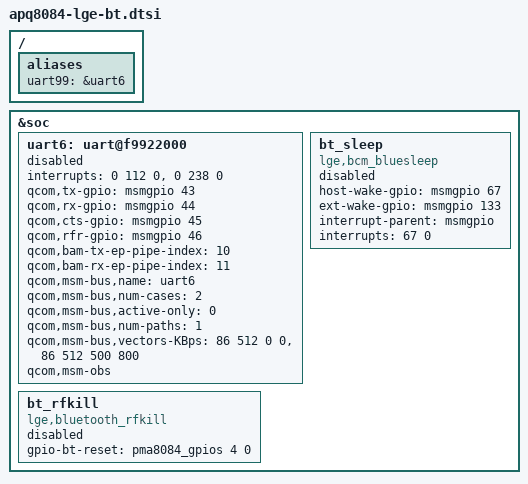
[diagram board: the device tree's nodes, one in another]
/* Copyright (c) 2012, Code Aurora Forum. All rights reserved.
 *
 * This program is free software; you can redistribute it and/or modify
 * it under the terms of the GNU General Public License version 2 and
 * only version 2 as published by the Free Software Foundation.
 *
 * This program is distributed in the hope that it will be useful,
 * but WITHOUT ANY WARRANTY; without even the implied warranty of
 * MERCHANTABILITY or FITNESS FOR A PARTICULAR PURPOSE.  See the
 * GNU General Public License for more details.
 */

/ {
	aliases {
		uart99 = &uart6;
	};
};

&soc {
	uart6: uart@f9922000 { //BLSP6
		status = "disable";
		interrupts = <0 112 0>, <0 238 0>;
		interrupt-names = "core_irq", "bam_irq";

		qcom,tx-gpio = <&msmgpio 43 0x00>;
		qcom,rx-gpio = <&msmgpio 44 0x00>;
		qcom,cts-gpio = <&msmgpio 45 0x00>;
		qcom,rfr-gpio = <&msmgpio 46 0x00>;

		qcom,bam-tx-ep-pipe-index = <10>;
		qcom,bam-rx-ep-pipe-index = <11>;

		qcom,msm-bus,name = "uart6";
		qcom,msm-bus,num-cases = <2>;
		qcom,msm-bus,active-only = <0>;
		qcom,msm-bus,num-paths = <1>;
		qcom,msm-bus,vectors-KBps =
				<86 512 0 0>,
				<86 512 500 800>;
		qcom,msm-obs;

		/delete-property/ interrupt-parent;
		/delete-property/ interrupt-map-mask;
		/delete-property/ interrupt-map;
	};

	/*To register rfkill*/
	bt_rfkill {
		compatible = "lge,bluetooth_rfkill";
		status = "disable";
		gpio-bt-reset = <&pma8084_gpios 4 0>;
	};


	/* To register BT wake-up devices for BT sleep */
	bt_sleep {
		compatible = "lge,bcm_bluesleep";
		status = "disable";
		host-wake-gpio = <&msmgpio 67 0>;
		ext-wake-gpio = <&msmgpio 133 0>;
		interrupt-parent = <&msmgpio>;
		interrupts = <67 0>;
		interrupt-names = "host_wake";
	};
};
